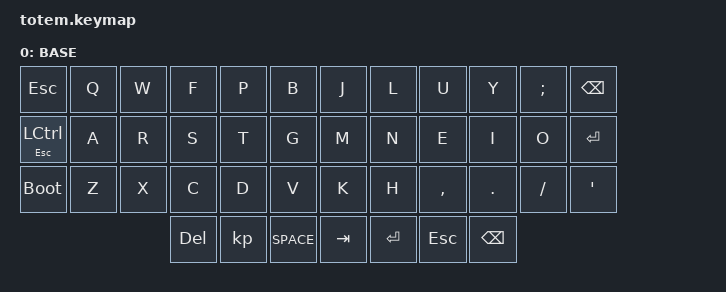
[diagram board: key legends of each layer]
#include <behaviors.dtsi>
#include <dt-bindings/zmk/bt.h>
#include <dt-bindings/zmk/keys.h>

#define BASE 0


/ {
   
    keymap {
        compatible = "zmk,keymap";

        // ▄▄▄▄▄▄▄▄▄▄▄▄▄▄▄▄▄▄▄▄▄▄▄▄▄▄▄▄▄▄▄▄▄▄▄▄▄▄▄▄▄▄▄▄▄▄▄▄▄▄▄▄▄▄▄▄▄▄▄▄▄▄▄▄▄▄▄▄▄▄▄▄▄▄▄▄▄▄▄▄▄▄▄▄▄▄▄▄▄▄▄▄▄▄▄▄▄▄▄▄▄▄▄▄▄▄▄▄▄▄▄▄▄▄▄▄▄▄▄▄▄▄▄▄▄▄▄▄▄▄▄▄▄▄▄▄▄▄▄▄▄▄▄▄▄▄▄▄▄

        base_layer {


            label = "BASE";

            bindings = <
      &kp ESC       &kp Q       &kp W       &kp F        &kp P        &kp B               &kp J    &kp L        &kp U        &kp Y       &kp SEMI   &kp BSPC
      &mt ESC LCTRL &kp A       &kp R       &kp S        &kp T        &kp G               &kp M    &kp N        &kp E        &kp I       &kp O      &kp ENTER
      &bootloader   &kp Z       &kp X       &kp C        &kp D        &kp V               &kp K    &kp H        &kp COMMA    &kp DOT     &kp FSLH   &kp SINGLE_QUOTE
                                            &kp DEL      kp SPACE     &kp TAB             &kp RET  &kp ESC      &kp BSPC
            >;
        };
    };
};
